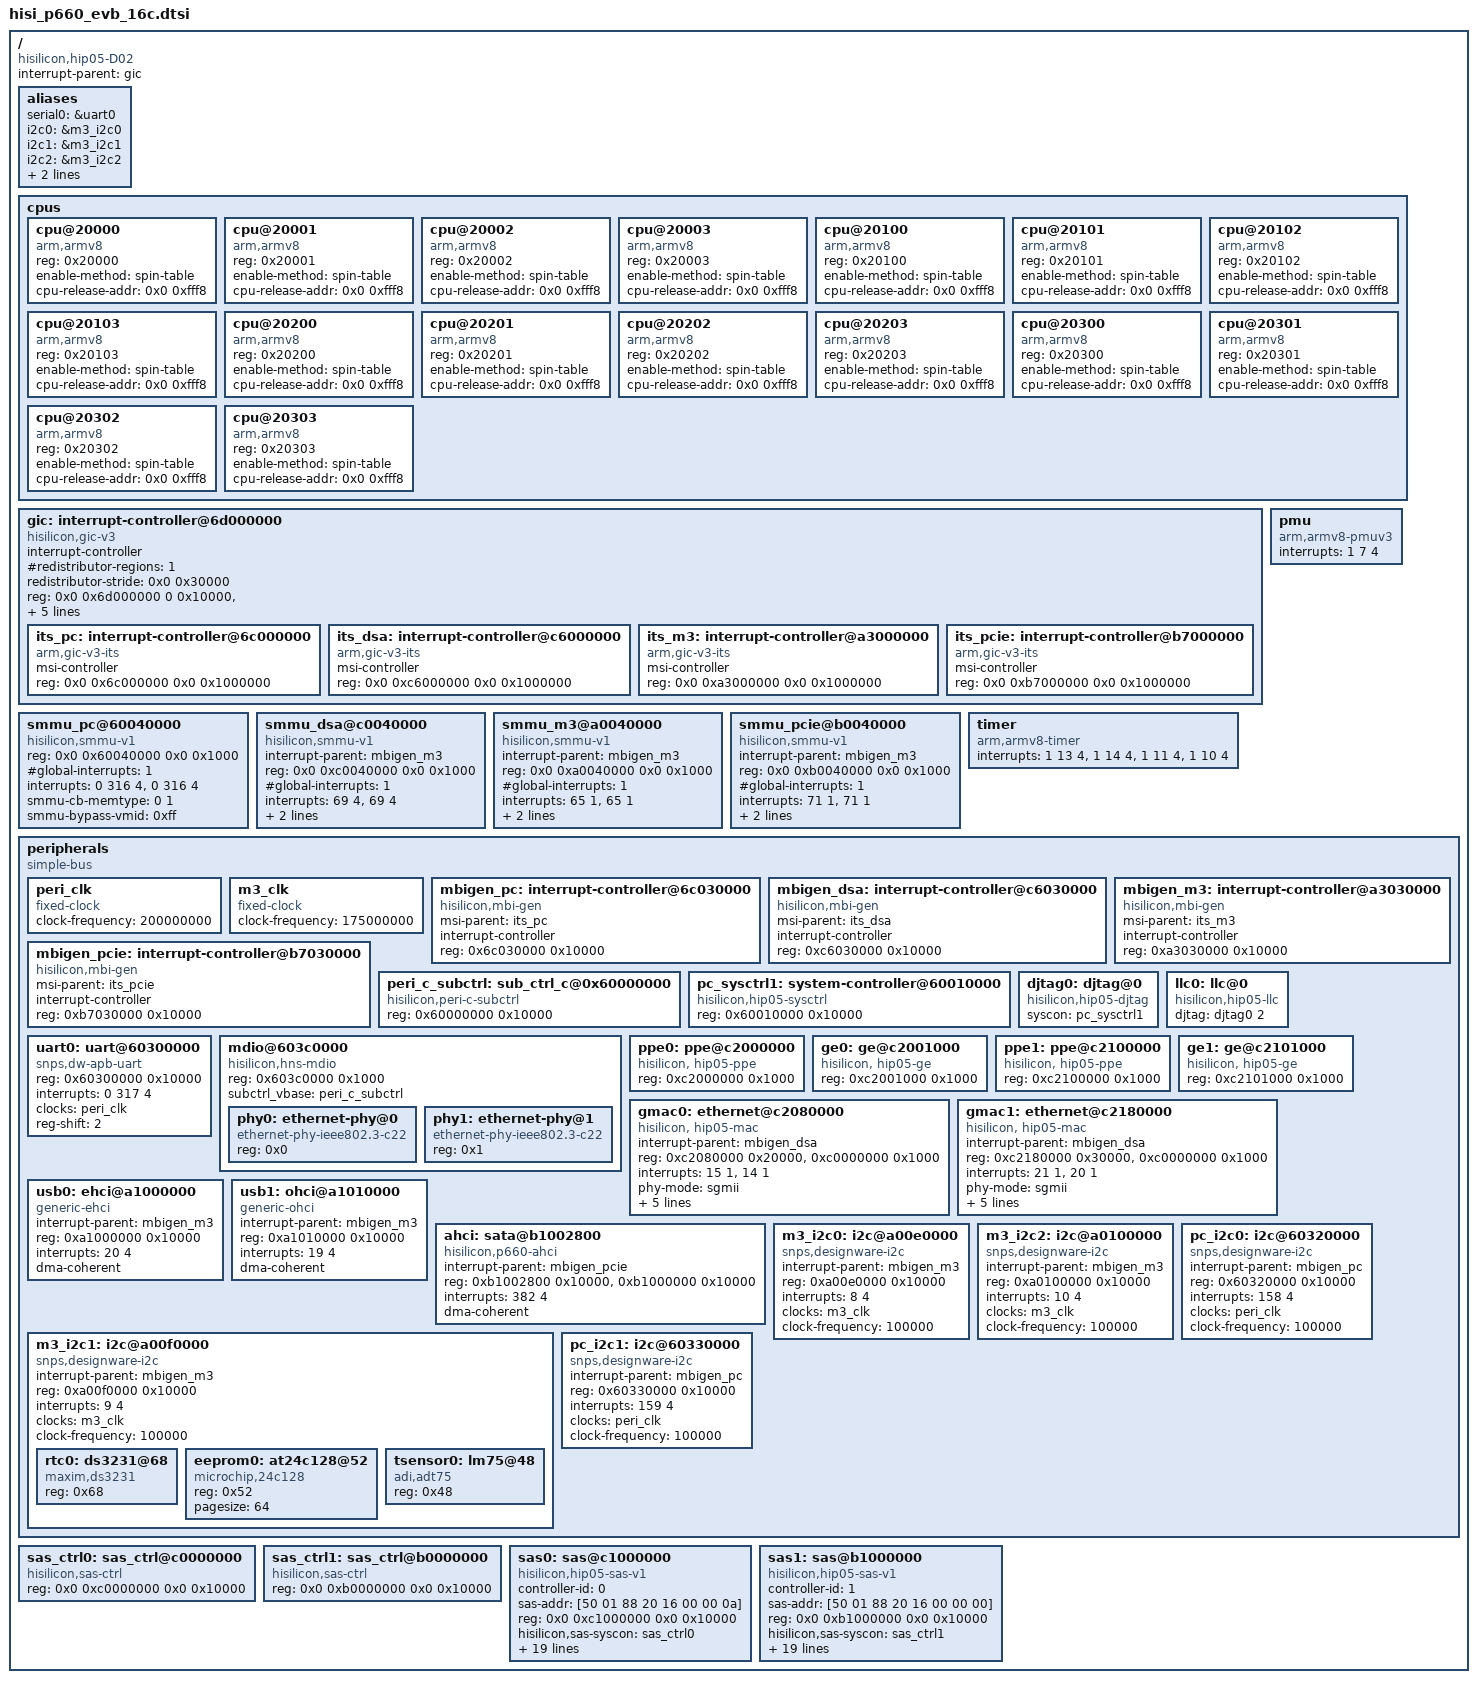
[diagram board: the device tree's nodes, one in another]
/**
 * dts file for Hisilicon PhosphorV660 16core Soc
 *
 * Copyright (C) 2014, Hisilicon Ltd.
 *
 * This program is free software; you can redistribute it and/or modify
 * it under the terms of the GNU General Public License version 2 as
 * publishhed by the Free Software Foundation.
 *
 */

/include/ "hisi_p660_pcie_evb.dtsi"

/ {
	#address-cells = <2>;
	#size-cells = <2>;
	compatible = "hisilicon,hip05-D02", "hisilicon,hisi-pv660";
	interrupt-parent = <&gic>;

	aliases {
		serial0 = &uart0;
		i2c0	= &m3_i2c0;
		i2c1	= &m3_i2c1;
		i2c2	= &m3_i2c2;
		i2c3	= &pc_i2c0;
		i2c4	= &pc_i2c1;
	};

	cpus {
		#address-cells = <1>;
		#size-cells = <0>;

		cpu@20000 {
			device_type = "cpu";
			compatible = "arm,armv8";
			reg = <0x20000>;
			enable-method = "spin-table";
			cpu-release-addr = <0x0 0xfff8>;
		};

		cpu@20001 {
			device_type = "cpu";
			compatible = "arm,armv8";
			reg = <0x20001>;
			enable-method = "spin-table";
			cpu-release-addr = <0x0 0xfff8>;
		};

		cpu@20002 {
			device_type = "cpu";
			compatible = "arm,armv8";
			reg = <0x20002>;
			enable-method = "spin-table";
			cpu-release-addr = <0x0 0xfff8>;
		};

		cpu@20003 {
			device_type = "cpu";
			compatible = "arm,armv8";
			reg = <0x20003>;
			enable-method = "spin-table";
			cpu-release-addr = <0x0 0xfff8>;
		};

		cpu@20100 {
			device_type = "cpu";
			compatible = "arm,armv8";
			reg = <0x20100>;
			enable-method = "spin-table";
			cpu-release-addr = <0x0 0xfff8>;
		};

		cpu@20101 {
			device_type = "cpu";
			compatible = "arm,armv8";
			reg = <0x20101>;
			enable-method = "spin-table";
			cpu-release-addr = <0x0 0xfff8>;
		};

		cpu@20102 {
			device_type = "cpu";
			compatible = "arm,armv8";
			reg = <0x20102>;
			enable-method = "spin-table";
			cpu-release-addr = <0x0 0xfff8>;
		};

		cpu@20103 {
			device_type = "cpu";
			compatible = "arm,armv8";
			reg = <0x20103>;
			enable-method = "spin-table";
			cpu-release-addr = <0x0 0xfff8>;
		};

		cpu@20200 {
			device_type = "cpu";
			compatible = "arm,armv8";
			reg = <0x20200>;
			enable-method = "spin-table";
			cpu-release-addr = <0x0 0xfff8>;
		};

		cpu@20201 {
			device_type = "cpu";
			compatible = "arm,armv8";
			reg = <0x20201>;
			enable-method = "spin-table";
			cpu-release-addr = <0x0 0xfff8>;
		};

		cpu@20202 {
			device_type = "cpu";
			compatible = "arm,armv8";
			reg = <0x20202>;
			enable-method = "spin-table";
			cpu-release-addr = <0x0 0xfff8>;
		};

		cpu@20203 {
			device_type = "cpu";
			compatible = "arm,armv8";
			reg = <0x20203>;
			enable-method = "spin-table";
			cpu-release-addr = <0x0 0xfff8>;
		};

		cpu@20300 {
			device_type = "cpu";
			compatible = "arm,armv8";
			reg = <0x20300>;
			enable-method = "spin-table";
			cpu-release-addr = <0x0 0xfff8>;
		};

		cpu@20301 {
			device_type = "cpu";
			compatible = "arm,armv8";
			reg = <0x20301>;
			enable-method = "spin-table";
			cpu-release-addr = <0x0 0xfff8>;
		};

		cpu@20302 {
			device_type = "cpu";
			compatible = "arm,armv8";
			reg = <0x20302>;
			enable-method = "spin-table";
			cpu-release-addr = <0x0 0xfff8>;
		};

		cpu@20303 {
			device_type = "cpu";
			compatible = "arm,armv8";
			reg = <0x20303>;
			enable-method = "spin-table";
			cpu-release-addr = <0x0 0xfff8>;
		};

	};

	gic: interrupt-controller@6d000000 {
		compatible = "hisilicon,gic-v3";
		#interrupt-cells = <3>;
		#address-cells = <2>;
		#size-cells = <2>;
		ranges;
		interrupt-controller;
		#redistributor-regions = <1>;
		redistributor-stride = <0x0 0x30000>;
		reg = <0x0 0x6d000000 0 0x10000>,	/* GICD */
		      <0x0 0x6d100000 0 0x300000>,	/* GICR c */
		      /*<0x0 0x4d100000 0 0x300000>,	GICR a */
		      <0x0 0xfe000000 0 0x10000>,	/* GICC */
		      <0x0 0xfe010000 0x0 0x10000>,     /* GICH */
		      <0x0 0xfe020000 0x0 0x10000>;     /* GICV */
		interrupts = <1 9 0xff04>;

		its_pc: interrupt-controller@6c000000 {
			compatible = "arm,gic-v3-its";
			msi-controller;
			reg = <0x0 0x6c000000 0x0 0x1000000>;
		};

		its_dsa: interrupt-controller@c6000000 {
			compatible = "arm,gic-v3-its";
			msi-controller;
			reg = <0x0 0xc6000000 0x0 0x1000000>;
		};

		its_m3: interrupt-controller@a3000000 {
			compatible = "arm,gic-v3-its";
			msi-controller;
			reg = <0x0 0xa3000000 0x0 0x1000000>;
		};

		its_pcie: interrupt-controller@b7000000 {
			compatible = "arm,gic-v3-its";
			msi-controller;
			reg = <0x0 0xb7000000 0x0 0x1000000>;
		};
	};

	smmu_pc@60040000 {
		compatible = "hisilicon,smmu-v1";
		reg = <0x0 0x60040000 0x0 0x1000>;
		#global-interrupts = <1>;
		interrupts = <0 316 4>,
			     <0 316 4>;
		smmu-cb-memtype = <0 1>;
		smmu-bypass-vmid = <0xff>;
	};

	smmu_dsa@c0040000 {
		compatible = "hisilicon,smmu-v1";
		interrupt-parent = <&mbigen_m3>;
		reg = <0x0 0xc0040000 0x0 0x1000>;
		#global-interrupts = <1>;
		interrupts = <69 4>,
			     <69 4>;
		smmu-cb-memtype = <0 1>;
		smmu-bypass-vmid = <0xff>;
	};

	smmu_m3@a0040000 {
		compatible = "hisilicon,smmu-v1";
		interrupt-parent = <&mbigen_m3>;
		reg = <0x0 0xa0040000 0x0 0x1000>;
		#global-interrupts = <1>;
		interrupts = <65 1>,
			     <65 1>;
		smmu-cb-memtype = <0 1>;
		smmu-bypass-vmid = <0xff>;
	};

	smmu_pcie@b0040000 {
		compatible = "hisilicon,smmu-v1";
		interrupt-parent = <&mbigen_m3>;
		reg = <0x0 0xb0040000 0x0 0x1000>;
		#global-interrupts = <1>;
		interrupts = <71 1>,
			     <71 1>;
		smmu-cb-memtype = <0 1>;
		smmu-bypass-vmid = <0xff>;
	};

	timer {
		compatible = "arm,armv8-timer";
		interrupts = <1 13 4>,
			     <1 14 4>,
			     <1 11 4>,
			     <1 10 4>;
	};

	pmu {
		compatible = "arm,armv8-pmuv3";
		interrupts = <1 7 4>;
	};


	peripherals {
		compatible = "simple-bus";
		#address-cells = <1>;
		#size-cells = <1>;
		ranges = <0x0 0x00000000 0x0 0xffffffff>;

		peri_clk: peri_clk {
			compatible = "fixed-clock";
			#clock-cells = <0>;
			clock-frequency = <200000000>;
		};

		m3_clk: m3_clk {
			compatible = "fixed-clock";
			#clock-cells = <0>;
			clock-frequency = <175000000>;
		};

		mbigen_pc: interrupt-controller@6c030000 {
			compatible = "hisilicon,mbi-gen";
			msi-parent = <&its_pc>;
			interrupt-controller;
			#interrupt-cells = <2>;
			reg = <0x6c030000 0x10000>;
		};

		mbigen_dsa: interrupt-controller@c6030000 {
			compatible = "hisilicon,mbi-gen";
			msi-parent = <&its_dsa>;
			interrupt-controller;
			#interrupt-cells = <2>;
			reg = <0xc6030000 0x10000>;
		};

		mbigen_m3: interrupt-controller@a3030000 {
			compatible = "hisilicon,mbi-gen";
			msi-parent = <&its_m3>;
			interrupt-controller;
			#interrupt-cells = <2>;
			reg = <0xa3030000 0x10000>;
		};

		mbigen_pcie: interrupt-controller@b7030000 {
			compatible = "hisilicon,mbi-gen";
			msi-parent = <&its_pcie>;
			interrupt-controller;
			#interrupt-cells = <2>;
			reg = <0xb7030000 0x10000>;
		};

		peri_c_subctrl: sub_ctrl_c@0x60000000 {
			compatible = "hisilicon,peri-c-subctrl", "syscon";
			reg = <0x60000000 0x10000>;
		};

		pc_sysctrl1: system-controller@60010000 {
			compatible = "hisilicon,hip05-sysctrl", "syscon";
			reg = <0x60010000 0x10000>;
		};

		djtag0: djtag@0 {
			compatible = "hisilicon,hip05-djtag";
			syscon = <&pc_sysctrl1>;
		};

		llc0: llc@0 {
			compatible = "hisilicon,hip05-llc";
			djtag = <&djtag0 2>;
		};

		uart0: uart@60300000 {
			compatible = "snps,dw-apb-uart";
			reg = <0x60300000 0x10000>;
			interrupts = <0 317 4>;
			clocks = <&peri_clk>;
			clock-names = "apb_pclk";
			reg-shift = <2>;
		};

		mdio@603c0000 {
			compatible = "hisilicon,hns-mdio";
			reg = <0x603c0000 0x1000>;
			subctrl_vbase = <&peri_c_subctrl>;
			#address-cells = <1>;
			#size-cells = <0>;

			phy0: ethernet-phy@0 {
				compatible = "ethernet-phy-ieee802.3-c22";
				reg = <0x0>;
			};

			phy1: ethernet-phy@1 {
				compatible = "ethernet-phy-ieee802.3-c22";
				reg = <0x1>;
			};
		};

		ppe0: ppe@c2000000 {
			compatible = "hisilicon, hip05-ppe", "syscon";
			reg = <0xc2000000 0x1000>;
		};

		ge0: ge@c2001000 {
			compatible = "hisilicon, hip05-ge", "syscon";
			reg = <0xc2001000 0x1000>;
		};

		ppe1: ppe@c2100000 {
			compatible = "hisilicon, hip05-ppe", "syscon";
			reg = <0xc2100000 0x1000>;
		};

		ge1: ge@c2101000 {
			compatible = "hisilicon, hip05-ge", "syscon";
			reg = <0xc2101000 0x1000>;
		};

		gmac0: ethernet@c2080000 {
			compatible = "hisilicon, hip05-mac";
			#address-cells = <1>;
			#size-cells = <0>;
			interrupt-parent = <&mbigen_dsa>;
			reg = <0xc2080000 0x20000>,
			      <0xc0000000 0x1000>;
			interrupts = <15 1>, /* rx irq */
				     <14 1>; /* tx irq */
			phy-mode = "sgmii";
			mac-address = [11 11 11 11 11 11];
			phy-handle = <&phy0>;
			ppe-handle = <&ppe0 0>;
			ge-handle = <&ge0 100 1>;
			dma-coherent;
		};

		gmac1: ethernet@c2180000 {
			compatible = "hisilicon, hip05-mac";
			#address-cells = <1>;
			#size-cells = <0>;
			interrupt-parent = <&mbigen_dsa>;
			reg = <0xc2180000 0x30000>,
			      <0xc0000000 0x1000>;
			interrupts = <21 1>, /* rx irq */
				     <20 1>; /* tx irq */
			phy-mode = "sgmii";
			mac-address = [11 11 11 11 11 11];
			phy-handle = <&phy1>;
			ppe-handle = <&ppe1 0>;
			ge-handle = <&ge1 100 1>;
			dma-coherent;
		};

		usb0: ehci@a1000000 {
			compatible = "generic-ehci";
			interrupt-parent = <&mbigen_m3>;
			reg = <0xa1000000 0x10000>;
			interrupts = <20 4>;
			dma-coherent;
		};

		usb1: ohci@a1010000 {
			compatible = "generic-ohci";
			interrupt-parent = <&mbigen_m3>;
			reg = <0xa1010000 0x10000>;
			interrupts = <19 4>;
			dma-coherent;
		};

		ahci: sata@b1002800 {
			compatible = "hisilicon,p660-ahci";
			interrupt-parent = <&mbigen_pcie>;
			reg = <0xb1002800 0x10000>,
			      <0xb1000000 0x10000>;
			interrupts = <382 4>;
			dma-coherent;
		};

		m3_i2c0: i2c@a00e0000 {
			#address-cells = <1>;
			#size-cells = <0>;
			compatible = "snps,designware-i2c";
			interrupt-parent = <&mbigen_m3>;
			reg = <0xa00e0000 0x10000>;
			interrupts = <8 4>;
			clocks = <&m3_clk>;
			clock-frequency = <100000>;
		};

		m3_i2c1: i2c@a00f0000 {
			#address-cells = <1>;
			#size-cells = <0>;
			compatible = "snps,designware-i2c";
			interrupt-parent = <&mbigen_m3>;
			reg = <0xa00f0000 0x10000>;
			interrupts = <9 4>;
			clocks = <&m3_clk>;
			clock-frequency = <100000>;

			rtc0: ds3231@68 {
				compatible = "maxim,ds3231";
				reg = <0x68>;
			};

			eeprom0: at24c128@52 {
				compatible = "microchip,24c128";
				reg = <0x52>;
				pagesize = <64>;
			};

			tsensor0: lm75@48 {
				compatible = "adi,adt75";
				reg = <0x48>;
			};
		};

		m3_i2c2: i2c@a0100000 {
			#address-cells = <1>;
			#size-cells = <0>;
			compatible = "snps,designware-i2c";
			interrupt-parent = <&mbigen_m3>;
			reg = <0xa0100000 0x10000>;
			interrupts = <10 4>;
			clocks = <&m3_clk>;
			clock-frequency = <100000>;
		};

		pc_i2c0: i2c@60320000 {
			#address-cells = <1>;
			#size-cells = <0>;
			compatible = "snps,designware-i2c";
			interrupt-parent = <&mbigen_pc>;
			reg = <0x60320000 0x10000>;
			interrupts = <158 4>;
			clocks = <&peri_clk>;
			clock-frequency = <100000>;
		};

		pc_i2c1: i2c@60330000 {
			#address-cells = <1>;
			#size-cells = <0>;
			compatible = "snps,designware-i2c";
			interrupt-parent = <&mbigen_pc>;
			reg = <0x60330000 0x10000>;
			interrupts = <159 4>;
			clocks = <&peri_clk>;
			clock-frequency = <100000>;
		};
	};

	sas_ctrl0: sas_ctrl@c0000000 {
		compatible = "hisilicon,sas-ctrl", "syscon";
		reg = <0x0 0xc0000000 0x0 0x10000>;
	};

	sas_ctrl1: sas_ctrl@b0000000 {
		compatible = "hisilicon,sas-ctrl", "syscon";
		reg = <0x0 0xb0000000 0x0 0x10000>;
	};

	sas0: sas@c1000000 {
		compatible = "hisilicon,hip05-sas-v1";
		controller-id = <0>;
		sas-addr = [50 01 88 20 16 00 00 0a];
		reg = <0x0 0xc1000000 0x0 0x10000>;
		hisilicon,sas-syscon = <&sas_ctrl0>;
		ctrl-reset-reg = <0xa60>;
		ctrl-reset-sts-reg = <0x5a30>;
		ctrl-clock-ena-reg = <0x338>;
		queue-count = <32>;
		phy-count = <8>;
		dma-coherent;
		interrupt-parent = <&mbigen_dsa>;
		interrupts = <259 4>, <263 4>,<264 4>,<265 4>,/* phy irq(0~79) */
				<269 4>, <273 4>,<274 4>,<275 4>,/* phy irq(0~79) */
				<279 4>, <283 4>,<284 4>,<285 4>,/* phy irq(0~79) */
				<289 4>, <293 4>,<294 4>,<295 4>,/* phy irq(0~79) */
				<299 4>, <303 4>,<304 4>,<305 4>,/* phy irq(0~79) */
				<309 4>, <313 4>,<314 4>,<315 4>,/* phy irq(0~79) */
				<319 4>, <323 4>,<324 4>,<325 4>,/* phy irq(0~79) */
				<329 4>, <333 4>,<334 4>,<335 4>,/* phy irq(0~79) */
				<336 1>, <337 1>,<338 1>,<339 1>,<340 1>,<341 1>,<342 1>,<343 1>,/* cq irq (80~111) */
				<344 1>, <345 1>,<346 1>,<347 1>,<348 1>,<349 1>,<350 1>,<351 1>,/* cq irq (80~111) */
				<352 1>, <353 1>,<354 1>,<355 1>,<356 1>,<357 1>,<358 1>,<359 1>,/* cq irq (80~111) */
				<360 1>, <361 1>,<362 1>,<363 1>,<364 1>,<365 1>,<366 1>,<367 1>,/* cq irq (80~111) */
				<376 4>, /* chip fatal error irq(120) */
				<381 4>; /* chip fatal error irq(125) */
		status = "okay";
	};

	sas1: sas@b1000000 {
		compatible = "hisilicon,hip05-sas-v1";
		controller-id = <1>;
		sas-addr = [50 01 88 20 16 00 00 00];
		reg = <0x0 0xb1000000 0x0 0x10000>;
		hisilicon,sas-syscon = <&sas_ctrl1>;
		ctrl-reset-reg = <0xa18>;
		ctrl-reset-sts-reg = <0x5a0c>;
		ctrl-clock-ena-reg = <0x318>;
		queue-count = <32>;
		phy-count = <8>;
		dma-coherent;
		interrupt-parent = <&mbigen_pcie>;
		interrupts = <259 4>, <263 4>,<264 4>,<265 4>,/* phy irq(0~79) */
				<269 4>, <273 4>,<274 4>,<275 4>,/* phy irq(0~79) */
				<279 4>, <283 4>,<284 4>,<285 4>,/* phy irq(0~79) */
				<289 4>, <293 4>,<294 4>,<295 4>,/* phy irq(0~79) */
				<299 4>, <303 4>,<304 4>,<305 4>,/* phy irq(0~79) */
				<309 4>, <313 4>,<314 4>,<315 4>,/* phy irq(0~79) */
				<319 4>, <323 4>,<324 4>,<325 4>,/* phy irq(0~79) */
				<329 4>, <333 4>,<334 4>,<335 4>,/* phy irq(0~79) */
				<336 1>, <337 1>,<338 1>,<339 1>,<340 1>,<341 1>,<342 1>,<343 1>,/* cq irq (80~111) */
				<344 1>, <345 1>,<346 1>,<347 1>,<348 1>,<349 1>,<350 1>,<351 1>,/* cq irq (80~111) */
				<352 1>, <353 1>,<354 1>,<355 1>,<356 1>,<357 1>,<358 1>,<359 1>,/* cq irq (80~111) */
				<360 1>, <361 1>,<362 1>,<363 1>,<364 1>,<365 1>,<366 1>,<367 1>,/* cq irq (80~111) */
				<376 4>, /* chip fatal error irq(120) */
				<381 4>; /* chip fatal error irq(125) */
		status = "okay";
	};
};
